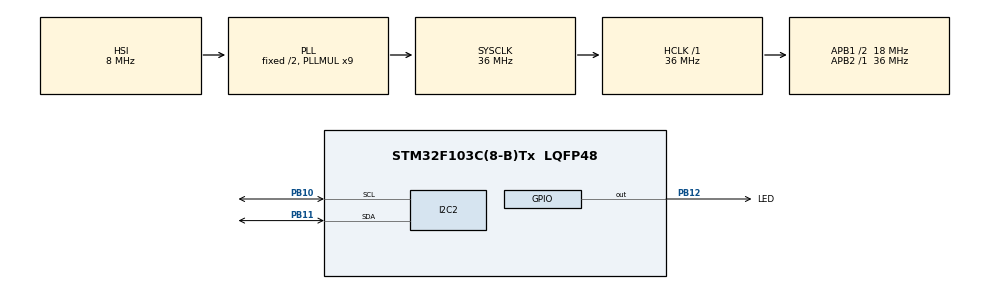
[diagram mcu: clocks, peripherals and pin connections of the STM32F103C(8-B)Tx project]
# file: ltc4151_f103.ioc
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I2C2.I2C_Mode=I2C_Fast
Mcu.Family=STM32F1
Mcu.Name=STM32F103C(8-B)Tx
Mcu.Package=LQFP48
NVIC.PriorityGroup=NVIC_PRIORITYGROUP_4
PA13.Mode=Serial_Wire
PA13.Signal=SYS_JTMS-SWDIO
PA14.Mode=Serial_Wire
PA14.Signal=SYS_JTCK-SWCLK
PB10.Mode=I2C
PB10.Signal=I2C2_SCL
PB11.Mode=I2C
PB11.Signal=I2C2_SDA
PB12.GPIO_Label=LED
PB12.Signal=GPIO_Output
PD0-OSC_IN.Mode=HSE-External-Clock-Source
PD0-OSC_IN.Signal=RCC_OSC_IN
PD1-OSC_OUT.Mode=HSE-External-Clock-Source
PD1-OSC_OUT.Signal=RCC_OSC_OUT
ProjectManager.HeapSize=0x200
ProjectManager.StackSize=0x400
ProjectManager.TargetToolchain=STM32CubeIDE
RCC.AHBFreq_Value=36000000
RCC.APB1CLKDivider=RCC_HCLK_DIV2
RCC.APB1Freq_Value=18000000
RCC.APB1TimFreq_Value=36000000
RCC.APB2Freq_Value=36000000
RCC.APB2TimFreq_Value=36000000
RCC.HCLKFreq_Value=36000000
RCC.PLLMUL=RCC_PLL_MUL9
RCC.SYSCLKFreq_VALUE=36000000
RCC.SYSCLKSource=RCC_SYSCLKSOURCE_PLLCLK
RCC.USBFreq_Value=36000000
board=custom

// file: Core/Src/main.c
/* USER CODE BEGIN Header */
/**
  ******************************************************************************
  * @file           : main.c
  * @brief          : Main program body
  ******************************************************************************
  * @attention
  *
  * Copyright (c) 2023 STMicroelectronics.
  * All rights reserved.
  *
  * This software is licensed under terms that can be found in the LICENSE file
  * in the root directory of this software component.
  * If no LICENSE file comes with this software, it is provided AS-IS.
  *
  ******************************************************************************
  */
/* USER CODE END Header */
#include "main.h"
#include "i2c.h"
#include "gpio.h"

/* USER CODE BEGIN Includes */
#include "ltc4151.h"
#include <stdlib.h>
/* USER CODE END Includes */

/* USER CODE BEGIN PD */
#define A0		0		//LTC4151 A0 Pin HIGH->1, LOW->0
#define A1		0		//LTC4151 A1 Pin HIGH->1, LOW->0
/* USER CODE END PD */

/* USER CODE BEGIN PV */
uint32_t tick, prev_tick;
uint32_t loop_rate = 2000;

LTC4151_t LTC4151;

uint16_t voltage = 0, voltage_snapshot = 0;
uint16_t current = 0, current_snapshot = 0;
uint16_t sense_resistor = 8;		//8 milli-ohms
//uint8_t buf[2];
//uint8_t h, l;
//uint16_t result;

uint8_t i, ret, i2c_add;

/* USER CODE END PV */

void SystemClock_Config(void);

/* USER CODE BEGIN 0 */
//uint16_t Read_ADC(LTC4151_t *ltc4151, uint16_t reg, uint16_t numOfBytes);
/* USER CODE END 0 */

int main(void)
{

  /* MCU Configuration--------------------------------------------------------*/

  /* Reset of all peripherals, Initializes the Flash interface and the Systick. */
  HAL_Init();

  /* Configure the system clock */
  SystemClock_Config();

  /* Initialize all configured peripherals */
  MX_GPIO_Init();
  MX_I2C2_Init();
  /* USER CODE BEGIN 2 */

  LTC4151_t_Init(hi2c2, &LTC4151, A0, A1, sense_resistor);

//    for(i = 1; i < 127; i++){
//    	ret = HAL_I2C_IsDeviceReady(&hi2c2, (uint16_t)(i<<1), 3, 5);
//		  if (ret == HAL_OK) /* No ACK Received At That Address */
//		  {
//			  i2c_add = i;
//		  }
//	}
  /* USER CODE END 2 */

  /* Infinite loop */
  /* USER CODE BEGIN WHILE */
  while (1)
  {
	  tick = HAL_GetTick();				//for debugging

	  voltage = Get_Input_Voltage(&LTC4151);
	  current = Get_Load_Current(&LTC4151);

	  if(tick - prev_tick >= loop_rate){
		  prev_tick = tick;
		  voltage_snapshot = Get_Snapshot_Input_Voltage(&LTC4151);
		  current_snapshot = Get_Snapshot_Load_Current(&LTC4151);
		  HAL_GPIO_TogglePin(LED_GPIO_Port, LED_Pin);
	  }
    /* USER CODE END WHILE */

  }
}

void SystemClock_Config(void)
{
  RCC_OscInitTypeDef RCC_OscInitStruct = {0};
  RCC_ClkInitTypeDef RCC_ClkInitStruct = {0};

  /** Initializes the RCC Oscillators according to the specified parameters
  * in the RCC_OscInitTypeDef structure.
  */
  RCC_OscInitStruct.OscillatorType = RCC_OSCILLATORTYPE_HSI;
  RCC_OscInitStruct.HSIState = RCC_HSI_ON;
  RCC_OscInitStruct.HSICalibrationValue = RCC_HSICALIBRATION_DEFAULT;
  RCC_OscInitStruct.PLL.PLLState = RCC_PLL_ON;
  RCC_OscInitStruct.PLL.PLLSource = RCC_PLLSOURCE_HSI_DIV2;
  RCC_OscInitStruct.PLL.PLLMUL = RCC_PLL_MUL9;
  if (HAL_RCC_OscConfig(&RCC_OscInitStruct) != HAL_OK)
  {
    Error_Handler();
  }

  /** Initializes the CPU, AHB and APB buses clocks
  */
  RCC_ClkInitStruct.ClockType = RCC_CLOCKTYPE_HCLK|RCC_CLOCKTYPE_SYSCLK
                              |RCC_CLOCKTYPE_PCLK1|RCC_CLOCKTYPE_PCLK2;
  RCC_ClkInitStruct.SYSCLKSource = RCC_SYSCLKSOURCE_PLLCLK;
  RCC_ClkInitStruct.AHBCLKDivider = RCC_SYSCLK_DIV1;
  RCC_ClkInitStruct.APB1CLKDivider = RCC_HCLK_DIV2;
  RCC_ClkInitStruct.APB2CLKDivider = RCC_HCLK_DIV1;

  if (HAL_RCC_ClockConfig(&RCC_ClkInitStruct, FLASH_LATENCY_1) != HAL_OK)
  {
    Error_Handler();
  }
}

void Error_Handler(void)
{
  __disable_irq();
  while (1)
  {
  }
}
